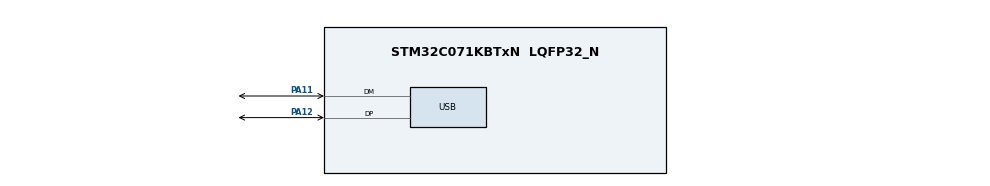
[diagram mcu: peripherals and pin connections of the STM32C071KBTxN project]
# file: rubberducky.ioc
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Mcu.Family=STM32C0
Mcu.Name=STM32C071KBTxN
Mcu.Package=LQFP32_N
PA11\ [PA9].Mode=Device
PA11\ [PA9].Signal=USB_DM
PA12\ [PA10].Mode=Device
PA12\ [PA10].Signal=USB_DP
ProjectManager.HeapSize=0x200
ProjectManager.StackSize=0x400
ProjectManager.TargetToolchain=CMake
RCC.ADCFreq_Value=12000000
RCC.AHBFreq_Value=12000000
RCC.CortexFreq_Value=12000000
RCC.EXTERNAL_CLOCK_VALUE=12288000
RCC.HCLKFreq_Value=12000000
RCC.HSE_VALUE=8000000
RCC.HSI48_VALUE=48000000
RCC.HSI_VALUE=48000000
RCC.LSE_VALUE=32768
RCC.SYSCLKFreq_VALUE=12000000
USB.VirtualMode=Device_Only
USBX.BSP.number=1
USBX.Core_System=1
USBX.UX_DEVICE_HID_CORE=1
USBX.UX_DEVICE_HID_KEYBOARD=1
USBX.UX_Device_Controller=1
USBX.UX_Device_CoreStack=1
USBX0.BSP.STBoard=false
USBX0.BSP.api=Unknown
USBX0.BSP.instance=USB
USBX0.BSP.ip=USB
USBX0.BSP.mode=Device_Only
USBX0.BSP.name=USB_Device
USBX0.BSP.solution=USB
VP_RCC_USB.Mode=CRS SYNC Source USB
VP_USBX_Core_System.Mode=Core_System
VP_USBX_UX\ Device\ Controller_FS.Mode=UX_Device_Controller_FS
VP_USBX_UX\ Device\ CoreStack_FS.Mode=UX_Device_CoreStack_FS
VP_USBX_UX\ Device\ HID_CORE_FS.Mode=UX_Device_class_HID_CORE_FS
VP_USBX_UX\ Device\ HID_KEYBOARD_FS.Mode=UX_Device_class_HID_KEYBOARD_FS
board=custom

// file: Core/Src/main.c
/* USER CODE BEGIN Header */
/**
  ******************************************************************************
  * @file           : main.c
  * @brief          : Main program body
  ******************************************************************************
  * @attention
  *
  * Copyright (c) 2026 STMicroelectronics.
  * All rights reserved.
  *
  * This software is licensed under terms that can be found in the LICENSE file
  * in the root directory of this software component.
  * If no LICENSE file comes with this software, it is provided AS-IS.
  *
  ******************************************************************************
  */
/* USER CODE END Header */
#include "main.h"
#include "app_usbx_device.h"

/* USER CODE BEGIN Includes */
#include "ux_device_keyboard.h"   /* for KEYBOARD_TypeA() */
/* USER CODE END Includes */

PCD_HandleTypeDef hpcd_USB_DRD_FS;

/* USER CODE BEGIN PV */
static uint32_t last_send_tick = 0;   // last type timestamp
/* USER CODE END PV */

void SystemClock_Config(void);
static void MX_GPIO_Init(void);

int main(void)
{

  /* MCU Configuration--------------------------------------------------------*/

  /* Reset of all peripherals, Initializes the Flash interface and the Systick. */
  HAL_Init();

  /* Configure the system clock */
  SystemClock_Config();

  /* Initialize all configured peripherals */
  MX_GPIO_Init();
  MX_USBX_Device_Init();
  /* USER CODE BEGIN 2 */

  // start USB hardware, assign endpoint packet memory, attach to USBX, go live
  MX_USB_PCD_Init();
  HAL_PCDEx_PMAConfig(&hpcd_USB_DRD_FS, 0x00U, PCD_SNG_BUF, 0x40U);   // control out
  HAL_PCDEx_PMAConfig(&hpcd_USB_DRD_FS, 0x80U, PCD_SNG_BUF, 0x80U);   // control in
  HAL_PCDEx_PMAConfig(&hpcd_USB_DRD_FS, USBD_HID_KEYBOARD_EPIN_ADDR, PCD_SNG_BUF, 0xC0U);  // key reports
  ux_dcd_stm32_initialize((ULONG)USB_DRD_FS, (ULONG)&hpcd_USB_DRD_FS);
  HAL_PCD_Start(&hpcd_USB_DRD_FS);   // enables D+ pull-up

  /* USER CODE END 2 */

  /* Infinite loop */
  while (1)
  {

    /* USER CODE BEGIN 3 */

    ux_system_tasks_run();   // sends queued reports, must run constantly

    // type "BEANS " 10x/s (12 reports/100ms, queue holds 16)
    if ((HAL_GetTick() - last_send_tick) >= 100U)
    {
      last_send_tick = HAL_GetTick();
      KEYBOARD_TypeString("BEANS ");
    }
  }
  /* USER CODE END 3 */
}

void SystemClock_Config(void)
{
  RCC_OscInitTypeDef RCC_OscInitStruct = {0};
  RCC_ClkInitTypeDef RCC_ClkInitStruct = {0};
  RCC_CRSInitTypeDef RCC_CRSInitStruct = {0};

  __HAL_FLASH_SET_LATENCY(FLASH_LATENCY_0);

  /** Initializes the RCC Oscillators according to the specified parameters
  * in the RCC_OscInitTypeDef structure.
  */
  RCC_OscInitStruct.OscillatorType = RCC_OSCILLATORTYPE_HSI|RCC_OSCILLATORTYPE_HSI48;
  RCC_OscInitStruct.HSIState = RCC_HSI_ON;
  RCC_OscInitStruct.HSIDiv = RCC_HSI_DIV4;
  RCC_OscInitStruct.HSICalibrationValue = RCC_HSICALIBRATION_DEFAULT;
  RCC_OscInitStruct.HSI48State = RCC_HSI48_ON;

  if (HAL_RCC_OscConfig(&RCC_OscInitStruct) != HAL_OK)
  {
    Error_Handler();
  }

  /** Initializes the CPU, AHB and APB buses clocks
  */
  RCC_ClkInitStruct.ClockType = RCC_CLOCKTYPE_HCLK|RCC_CLOCKTYPE_SYSCLK
                              |RCC_CLOCKTYPE_PCLK1;
  RCC_ClkInitStruct.SYSCLKSource = RCC_SYSCLKSOURCE_HSI;
  RCC_ClkInitStruct.SYSCLKDivider = RCC_SYSCLK_DIV1;
  RCC_ClkInitStruct.AHBCLKDivider = RCC_HCLK_DIV1;
  RCC_ClkInitStruct.APB1CLKDivider = RCC_APB1_DIV1;

  if (HAL_RCC_ClockConfig(&RCC_ClkInitStruct, FLASH_LATENCY_0) != HAL_OK)
  {
    Error_Handler();
  }

  /** Enable the CRS APB clock
  */
  __HAL_RCC_CRS_CLK_ENABLE();

  /** Configures CRS
  */
  RCC_CRSInitStruct.Prescaler = RCC_CRS_SYNC_DIV1;
  RCC_CRSInitStruct.Source = RCC_CRS_SYNC_SOURCE_USB;
  RCC_CRSInitStruct.Polarity = RCC_CRS_SYNC_POLARITY_RISING;
  RCC_CRSInitStruct.ReloadValue = __HAL_RCC_CRS_RELOADVALUE_CALCULATE(48000000,1000);
  RCC_CRSInitStruct.ErrorLimitValue = 34;
  RCC_CRSInitStruct.HSI48CalibrationValue = 32;

  HAL_RCCEx_CRSConfig(&RCC_CRSInitStruct);
}

void MX_USB_PCD_Init(void)
{

  hpcd_USB_DRD_FS.Instance = USB_DRD_FS;
  hpcd_USB_DRD_FS.Init.dev_endpoints = 8;
  hpcd_USB_DRD_FS.Init.speed = USBD_FS_SPEED;
  hpcd_USB_DRD_FS.Init.phy_itface = PCD_PHY_EMBEDDED;
  hpcd_USB_DRD_FS.Init.Sof_enable = DISABLE;
  hpcd_USB_DRD_FS.Init.low_power_enable = DISABLE;
  hpcd_USB_DRD_FS.Init.lpm_enable = DISABLE;
  hpcd_USB_DRD_FS.Init.battery_charging_enable = DISABLE;
  hpcd_USB_DRD_FS.Init.vbus_sensing_enable = DISABLE;
  hpcd_USB_DRD_FS.Init.bulk_doublebuffer_enable = DISABLE;
  hpcd_USB_DRD_FS.Init.iso_singlebuffer_enable = DISABLE;
  if (HAL_PCD_Init(&hpcd_USB_DRD_FS) != HAL_OK)
  {
    Error_Handler();
  }

}

static void MX_GPIO_Init(void)
{

  /* GPIO Ports Clock Enable */
  __HAL_RCC_GPIOA_CLK_ENABLE();

}

void Error_Handler(void)
{
  __disable_irq();
  while (1)
  {
  }
}
